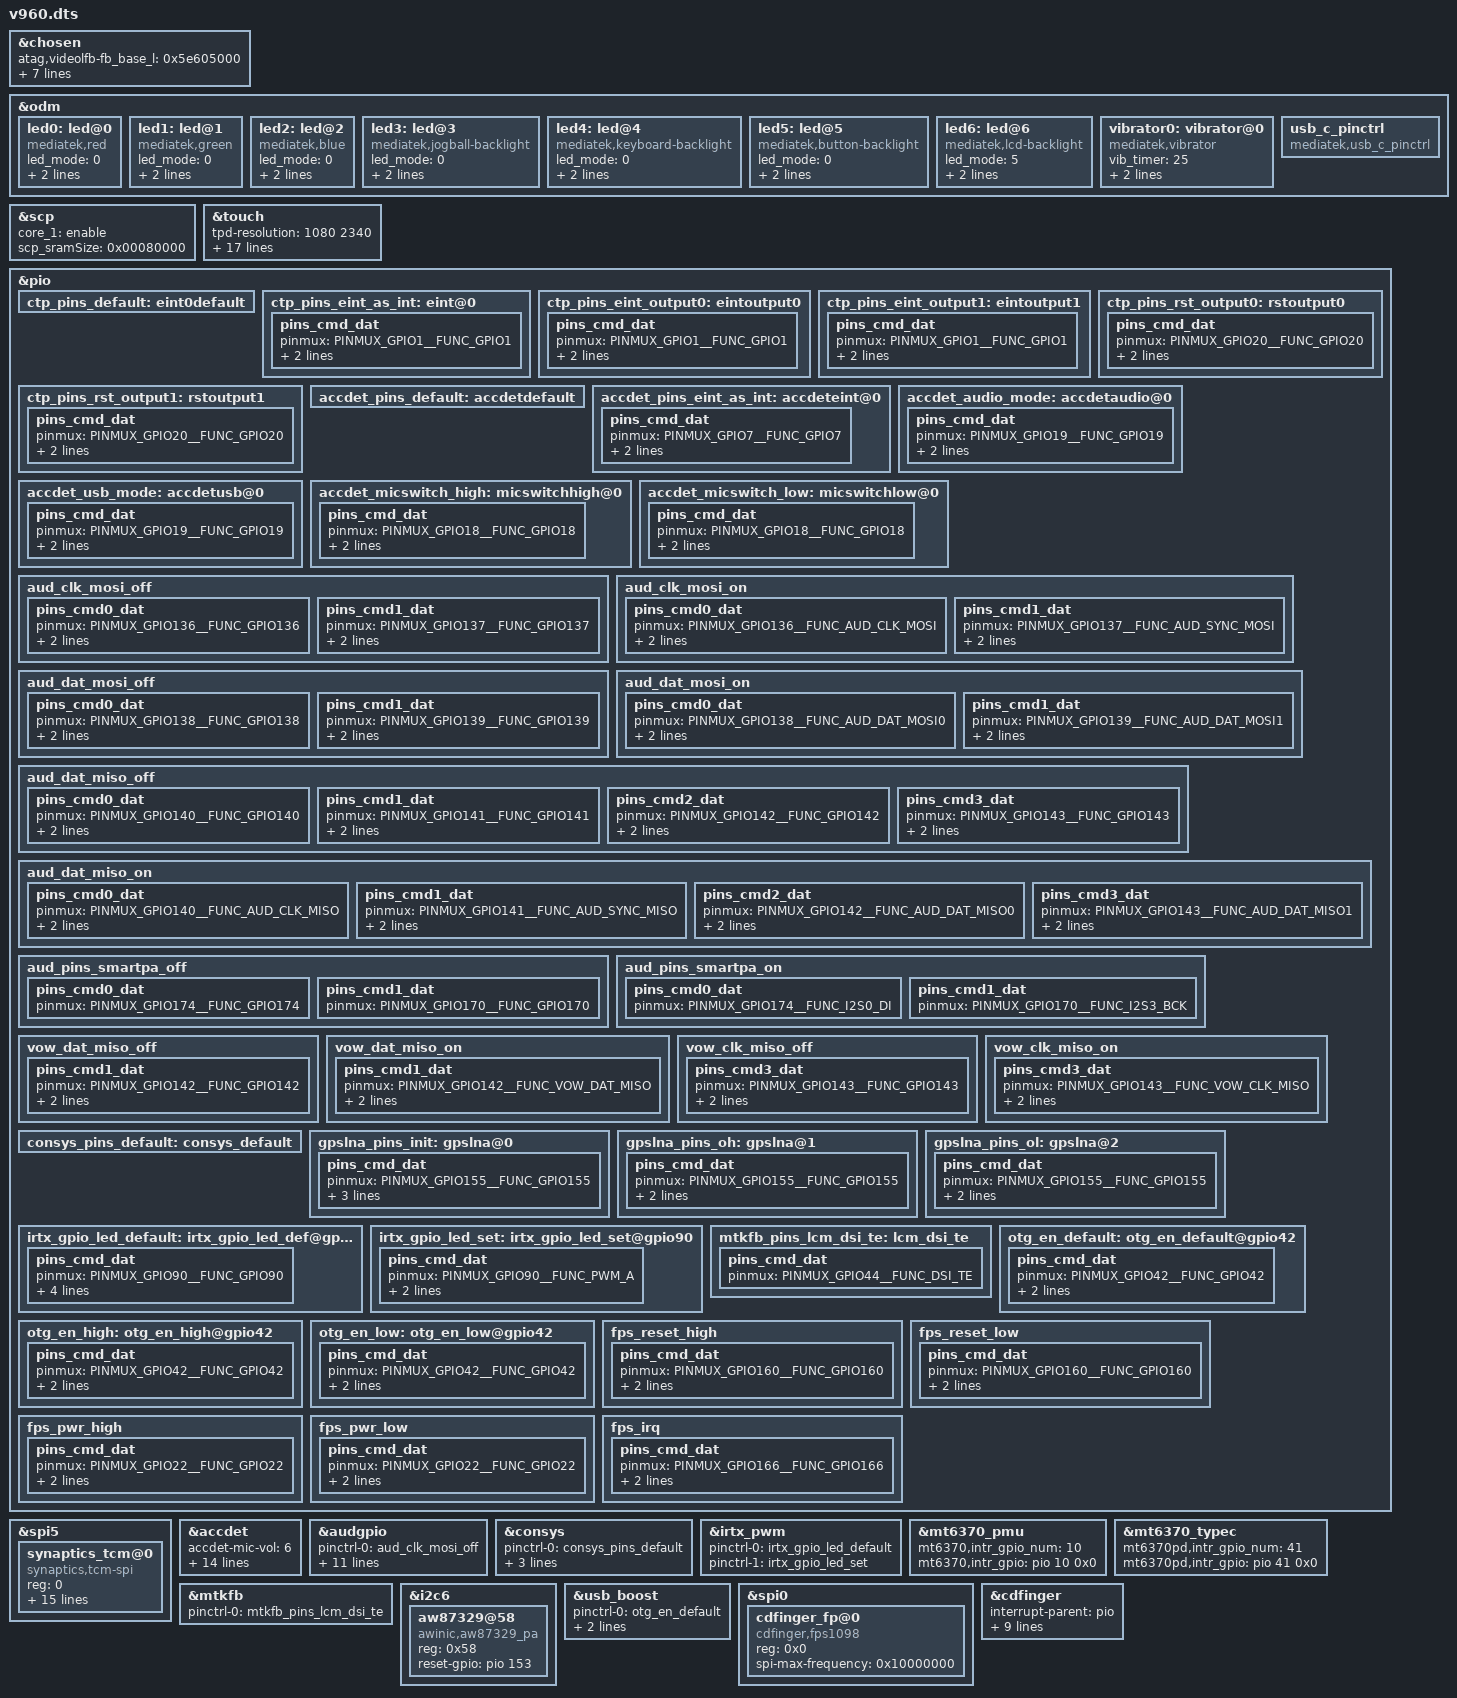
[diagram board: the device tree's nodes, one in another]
/*
 * Mediatek's mt6771 SoC device tree source
 *
 * Copyright (C) 2016 MediaTek Inc.
 *
 * This program is free software; you can redistribute it and/or modify
 * it under the terms of the GNU General Public License version 2 as
 * published by the Free Software Foundation.
 *
 * This program is distributed in the hope that it will be useful,
 * but WITHOUT ANY WARRANTY; without even the implied warranty of
 * MERCHANTABILITY or FITNESS FOR A PARTICULAR PURPOSE.
 * See http://www.gnu.org/licenses/gpl-2.0.html for more details.
 */
/dts-v1/;
/plugin/;
#include <dt-bindings/interrupt-controller/irq.h>
#include <dt-bindings/interrupt-controller/arm-gic.h>
#include <dt-bindings/pinctrl/mt6771-pinfunc.h>

/* chosen */
&chosen {
	/* fpga may has no lk, we need to specify display info here */
	/* fb buffer is reserved using this dts by memory node above */

	atag,videolfb-fb_base_l = <0x5e605000>;
	atag,videolfb-fb_base_h = <0x0>;
	atag,videolfb-islcmfound = <1>;
	atag,videolfb-islcm_inited = <0>;
	atag,videolfb-fps= <6000>;
	atag,videolfb-vramSize= <0x017bb000>;
	atag,videolfb-lcmname= "nt35595_fhd_dsi_cmd_truly_nt50358_drv";
};

&odm {
	led0:led@0 {
		compatible = "mediatek,red";
		led_mode = <0>;
		data = <1>;
		pwm_config = <0 0 0 0 0>;
	};
	led1:led@1 {
		compatible = "mediatek,green";
		led_mode = <0>;
		data = <1>;
		pwm_config = <0 0 0 0 0>;
	};
	led2:led@2 {
		compatible = "mediatek,blue";
		led_mode = <0>;
		data = <1>;
		pwm_config = <0 0 0 0 0>;
	};
	led3:led@3 {
		compatible = "mediatek,jogball-backlight";
		led_mode = <0>;
		data = <1>;
		pwm_config = <0 0 0 0 0>;
	};
	led4:led@4 {
		compatible = "mediatek,keyboard-backlight";
		led_mode = <0>;
		data = <1>;
		pwm_config = <0 0 0 0 0>;
	};
	led5:led@5 {
		compatible = "mediatek,button-backlight";
		led_mode = <0>;
		data = <1>;
		pwm_config = <0 0 0 0 0>;
	};
	led6:led@6 {
		compatible = "mediatek,lcd-backlight";
		led_mode = <5>;
		data = <1>;
		pwm_config = <0 1 0 0 0>;
	};
	vibrator0:vibrator@0 {
		compatible = "mediatek,vibrator";
		vib_timer = <25>;
		vib_limit = <9>;
		vib_vol= <9>;
	};
	usb_c_pinctrl:usb_c_pinctrl {
		compatible = "mediatek,usb_c_pinctrl";
	};
};

&scp {
	core_1 = "enable";
	scp_sramSize = <0x00080000>;     /* scp_A_sram_size */
};

/* TOUCH start */
&touch {
	tpd-resolution = <1080 2340>;
	use-tpd-button = <0>;
	tpd-key-num = <3>;
	tpd-key-local= <139 172 158 0>;
	tpd-key-dim-local = <90 883 100 40 230 883 100 40 370 883 100 40 0 0 0 0>;
	tpd-max-touch-num = <5>;
	tpd-filter-enable = <1>;
	tpd-filter-pixel-density = <146>;
	tpd-filter-custom-prameters = <0 0 0 0 0 0 0 0 0 0 0 0>;
	tpd-filter-custom-speed = <0 0 0>;
	pinctrl-names = "default", "state_eint_as_int",
		"state_eint_output0", "state_eint_output1",
		"state_rst_output0", "state_rst_output1";
	pinctrl-0 = <&ctp_pins_default>;
	pinctrl-1 = <&ctp_pins_eint_as_int>;
	pinctrl-2 = <&ctp_pins_eint_output0>;
	pinctrl-3 = <&ctp_pins_eint_output1>;
	pinctrl-4 = <&ctp_pins_rst_output0>;
	pinctrl-5 = <&ctp_pins_rst_output1>;
	status = "okay";
};
&pio {
	ctp_pins_default: eint0default {
	};
	ctp_pins_eint_as_int: eint@0 {
		pins_cmd_dat {
			pinmux = <PINMUX_GPIO1__FUNC_GPIO1>;
			slew-rate = <0>;
			bias-disable;
		};
	};
	ctp_pins_eint_output0: eintoutput0 {
		pins_cmd_dat {
			pinmux = <PINMUX_GPIO1__FUNC_GPIO1>;
			slew-rate = <1>;
			output-low;
		};
	};
	ctp_pins_eint_output1: eintoutput1 {
		pins_cmd_dat {
			pinmux = <PINMUX_GPIO1__FUNC_GPIO1>;
			slew-rate = <1>;
			output-high;
		};
	};
	ctp_pins_rst_output0: rstoutput0 {
		pins_cmd_dat {
			pinmux = <PINMUX_GPIO20__FUNC_GPIO20>;
			slew-rate = <1>;
			output-low;
		};
	};
	ctp_pins_rst_output1: rstoutput1 {
		pins_cmd_dat {
			pinmux = <PINMUX_GPIO20__FUNC_GPIO20>;
			slew-rate = <1>;
			output-high;
		};
	};
};

&spi5{
	#address-cells = <1>;
	#size-cells = <0>;
	status = "okay";
	synaptics_tcm@0 {
		compatible = "synaptics,tcm-spi";
		reg = <0>;
		spi-max-frequency = <8000000>;
		interrupt-parent = <&pio>;
		interrupts = <1 0x2008>;
		synaptics,irq-gpio = <&pio 1 0x2008>; /* IRQF_ONESHOT | IRQF_TRIGGER_LOW */
		synaptics,irq-on-state = <0>;
		synaptics,reset-gpio = <&pio 20 0x0000>;
		synaptics,reset-on-state = <0>;
		synaptics,reset-active-ms = <20>;
		synaptics,reset-delay-ms = <200>;
		synaptics,power-delay-ms = <200>;
		synaptics,spi-mode = <3>;
		synaptics,byte-delay-us = <0>;
		synaptics,block-delay-us = <0>;
		synaptics,ubl-max-freq = <100000>;
		synaptics,ubl-byte-delay-us = <0>;
		status = "okay";
	};
};
/* TOUCH end */

/* accdet start */
&accdet {
	/* accdet micbias voltage: 0x07,2.7v;0x05,2.5v;0x02,1.9v */
	accdet-mic-vol = <6>;
	headset-mode-setting = <0x500 0x500 1 0x1f0 0x800 0x800 0x20 0x44>;
	accdet-plugout-debounce = <1>;
	/*1:ACC mode, 2:low cost without in bias, 6:low cost with in bias*/
	accdet-mic-mode = <1>;
	/* eint_level_trigger: 8,LEVEL_LOW(default);4,LEVEL_HIGH;others,LEVEL_LOW */
	headset-eint-level-pol = <8>;
	/*0--MD_MAX--UP_MAX--DW_MAX*/
	headset-three-key-threshold = <0 60 200 400>;
	headset-three-key-threshold-CDD = <0 121 192 600>;
	/*0--MD_MAX--VOICE_MAX--UP_MAX--DW_MAX*/
	headset-four-key-threshold = <0 58 121 192 400>;

	pinctrl-names = "default", "state_eint_as_int", "state_audio_mode", "state_usb_mode", "state_micswitch_high", "state_micswitch_low";
	pinctrl-0 = <&accdet_pins_default>;
	pinctrl-1 = <&accdet_pins_eint_as_int>;
	pinctrl-2 = <&accdet_audio_mode>;
	pinctrl-3 = <&accdet_usb_mode>;
	pinctrl-4 = <&accdet_micswitch_high>;
	pinctrl-5 = <&accdet_micswitch_low>;
	status = "okay";
};
&pio {
	accdet_pins_default: accdetdefault {
	};
	accdet_pins_eint_as_int: accdeteint@0 {
		pins_cmd_dat {
			pinmux = <PINMUX_GPIO7__FUNC_GPIO7>;
			slew-rate = <0>;
			bias-disable;
		};
	};
	accdet_audio_mode: accdetaudio@0 {
		pins_cmd_dat {
			pinmux = <PINMUX_GPIO19__FUNC_GPIO19>;
			slew-rate = <1>;
			output-high;
		};
	};
	accdet_usb_mode: accdetusb@0 {
		pins_cmd_dat {
			pinmux = <PINMUX_GPIO19__FUNC_GPIO19>;
			slew-rate = <1>;
			output-low;
		};
	};
	accdet_micswitch_high: micswitchhigh@0 {
		pins_cmd_dat {
			pinmux = <PINMUX_GPIO18__FUNC_GPIO18>;
			slew-rate = <1>;
			output-high;
		};
	};
	accdet_micswitch_low: micswitchlow@0 {
		pins_cmd_dat {
			pinmux = <PINMUX_GPIO18__FUNC_GPIO18>;
			slew-rate = <1>;
			output-low;
		};
	};
};
/* accdet end */

/* AUDIO GPIO standardization */
&audgpio {
	pinctrl-names = "aud_clk_mosi_off",
			"aud_clk_mosi_on",
			"aud_dat_mosi_off",
			"aud_dat_mosi_on",
			"aud_dat_miso_off",
			"aud_dat_miso_on",
			"aud_smartpa_off",
			"aud_smartpa_on",
			"vow_dat_miso_off",
			"vow_dat_miso_on",
			"vow_clk_miso_off",
			"vow_clk_miso_on";
	pinctrl-0 = <&aud_clk_mosi_off>;
	pinctrl-1 = <&aud_clk_mosi_on>;
	pinctrl-2 = <&aud_dat_mosi_off>;
	pinctrl-3 = <&aud_dat_mosi_on>;
	pinctrl-4 = <&aud_dat_miso_off>;
	pinctrl-5 = <&aud_dat_miso_on>;
	pinctrl-6 = <&aud_pins_smartpa_off>;
	pinctrl-7 = <&aud_pins_smartpa_on>;
	pinctrl-8 = <&vow_dat_miso_off>;
	pinctrl-9 = <&vow_dat_miso_on>;
	pinctrl-10 = <&vow_clk_miso_off>;
	pinctrl-11 = <&vow_clk_miso_on>;
	status = "okay";
};

&pio {
	aud_clk_mosi_off: aud_clk_mosi_off {
		pins_cmd0_dat {
			pinmux = <PINMUX_GPIO136__FUNC_GPIO136>;
			input-enable;
			bias-pull-down;
		};
		pins_cmd1_dat {
			pinmux = <PINMUX_GPIO137__FUNC_GPIO137>;
			input-enable;
			bias-pull-down;
		};
	};

	aud_clk_mosi_on: aud_clk_mosi_on {
		pins_cmd0_dat {
			pinmux = <PINMUX_GPIO136__FUNC_AUD_CLK_MOSI>;
			input-schmitt-enable;
			bias-disable;
		};
		pins_cmd1_dat {
			pinmux = <PINMUX_GPIO137__FUNC_AUD_SYNC_MOSI>;
			input-schmitt-enable;
			bias-disable;
		};
	};

	aud_dat_mosi_off: aud_dat_mosi_off {
		pins_cmd0_dat {
			pinmux = <PINMUX_GPIO138__FUNC_GPIO138>;
			input-enable;
			bias-disable;
		};
		pins_cmd1_dat {
			pinmux = <PINMUX_GPIO139__FUNC_GPIO139>;
			input-enable;
			bias-pull-down;
		};
	};

	aud_dat_mosi_on: aud_dat_mosi_on {
		pins_cmd0_dat {
			pinmux = <PINMUX_GPIO138__FUNC_AUD_DAT_MOSI0>;
			input-schmitt-enable;
			bias-disable;
		};
		pins_cmd1_dat {
			pinmux = <PINMUX_GPIO139__FUNC_AUD_DAT_MOSI1>;
			input-schmitt-enable;
			bias-disable;
		};
	};

	aud_dat_miso_off: aud_dat_miso_off {
		pins_cmd0_dat {
			pinmux = <PINMUX_GPIO140__FUNC_GPIO140>;
			input-enable;
			bias-disable;
		};
		pins_cmd1_dat {
			pinmux = <PINMUX_GPIO141__FUNC_GPIO141>;
			input-enable;
			bias-disable;
		};
		pins_cmd2_dat {
			pinmux = <PINMUX_GPIO142__FUNC_GPIO142>;
			input-enable;
			bias-disable;
		};
		pins_cmd3_dat {
			pinmux = <PINMUX_GPIO143__FUNC_GPIO143>;
			input-enable;
			bias-disable;
		};
	};

	aud_dat_miso_on: aud_dat_miso_on {
		pins_cmd0_dat {
			pinmux = <PINMUX_GPIO140__FUNC_AUD_CLK_MISO>;
			input-schmitt-enable;
			bias-disable;
		};
		pins_cmd1_dat {
			pinmux = <PINMUX_GPIO141__FUNC_AUD_SYNC_MISO>;
			input-schmitt-enable;
			bias-disable;
		};
		pins_cmd2_dat {
			pinmux = <PINMUX_GPIO142__FUNC_AUD_DAT_MISO0>;
			input-schmitt-enable;
			bias-disable;
		};
		pins_cmd3_dat {
			pinmux = <PINMUX_GPIO143__FUNC_AUD_DAT_MISO1>;
			input-schmitt-enable;
			bias-disable;
		};
	};

	aud_pins_smartpa_off: aud_pins_smartpa_off {
		pins_cmd0_dat {
			pinmux = <PINMUX_GPIO174__FUNC_GPIO174>;
		};
		pins_cmd1_dat {
			pinmux = <PINMUX_GPIO170__FUNC_GPIO170>;
		};
	};

	aud_pins_smartpa_on: aud_pins_smartpa_on {
		pins_cmd0_dat {
			pinmux = <PINMUX_GPIO174__FUNC_I2S0_DI>;
		};
		pins_cmd1_dat {
			pinmux = <PINMUX_GPIO170__FUNC_I2S3_BCK>;
		};
	};

	vow_dat_miso_off: vow_dat_miso_off {
		pins_cmd1_dat {
			pinmux = <PINMUX_GPIO142__FUNC_GPIO142>;
			input-enable;
			bias-pull-down;
		};
	};

	vow_dat_miso_on: vow_dat_miso_on {
		pins_cmd1_dat {
			pinmux = <PINMUX_GPIO142__FUNC_VOW_DAT_MISO>;
			input-schmitt-enable;
			bias-disable;
		};
	};

	vow_clk_miso_off: vow_clk_miso_off {
		pins_cmd3_dat {
			pinmux = <PINMUX_GPIO143__FUNC_GPIO143>;
			input-enable;
			bias-pull-down;
		};
	};

	vow_clk_miso_on: vow_clk_miso_on {
		pins_cmd3_dat {
			pinmux = <PINMUX_GPIO143__FUNC_VOW_CLK_MISO>;
			input-schmitt-enable;
			bias-disable;
		};
	};
};
/* AUDIO end */

/* CONSYS GPIO standardization */
&pio {
	consys_pins_default: consys_default {
	};
	gpslna_pins_init: gpslna@0 {
		pins_cmd_dat {
			pinmux = <PINMUX_GPIO155__FUNC_GPIO155>;
			slew-rate = <0>;
			bias-disable;
			output-low;
		};
	};
	gpslna_pins_oh: gpslna@1 {
		pins_cmd_dat {
			pinmux = <PINMUX_GPIO155__FUNC_GPIO155>;
			slew-rate = <1>;
			output-high;
		};
	};
	gpslna_pins_ol: gpslna@2 {
		pins_cmd_dat {
			pinmux = <PINMUX_GPIO155__FUNC_GPIO155>;
			slew-rate = <1>;
			output-low;
		};
	};
};
&consys {
	pinctrl-names = "default", "gps_lna_state_init", "gps_lna_state_oh", "gps_lna_state_ol";
	pinctrl-0 = <&consys_pins_default>;
	pinctrl-1 = <&gpslna_pins_init>;
	pinctrl-2 = <&gpslna_pins_oh>;
	pinctrl-3 = <&gpslna_pins_ol>;
	status = "okay";
};
/* CONSYS end */

/* IRTX GPIO Start */
&irtx_pwm {
	pinctrl-names = "irtx_gpio_led_default", "irtx_gpio_led_set";
	pinctrl-0 = <&irtx_gpio_led_default>;
	pinctrl-1 = <&irtx_gpio_led_set>;
	status = "okay";
};
&pio {
	/* IRTX GPIO Settings -Start */
	/* default: GPIO0, output, high */
	irtx_gpio_led_default:irtx_gpio_led_def@gpio90 {
		pins_cmd_dat {
			pinmux = <PINMUX_GPIO90__FUNC_GPIO90>;
			slew-rate = <1>;
			bias-disable;
			output-low;
			input-schmitt-enable = <0>;
		};
	};

	irtx_gpio_led_set:irtx_gpio_led_set@gpio90 {
		pins_cmd_dat {
			pinmux = <PINMUX_GPIO90__FUNC_PWM_A>;
			slew-rate = <1>;
			output-high;
		};
	};
}; /* IRTX GPIO Settings -End */

&mt6370_pmu {
	mt6370,intr_gpio_num = <10>; /* direct defined GPIO num */
	mt6370,intr_gpio = <&pio 10 0x0>;
};

&mt6370_typec {
	mt6370pd,intr_gpio_num = <41>; /* direct defined GPIO num */
	mt6370pd,intr_gpio = <&pio 41 0x0>;
};

&pio {
	mtkfb_pins_lcm_dsi_te: lcm_dsi_te {
		pins_cmd_dat {
			pinmux = <PINMUX_GPIO44__FUNC_DSI_TE>;
		};
	};
};

&mtkfb {
	pinctrl-names = "mode_te_te";
	pinctrl-0 = <&mtkfb_pins_lcm_dsi_te>;
	status = "okay";
};

/* AW83729 Smart PA start */
&i2c6 {
	aw87329@58 {
		compatible = "awinic,aw87329_pa";
		reg = <0x58>;
		reset-gpio = <&pio 153 0>;
		status = "okay";
	};
};
/* AW83729 Smart PA end */

/* usb_boost_manager otg_en Start */
&usb_boost {
	pinctrl-names = "otg_en_default","drvvbus_high","drvvbus_low";
	pinctrl-0 = <&otg_en_default>;
	pinctrl-1 = <&otg_en_high>;
	pinctrl-2 = <&otg_en_low>;
	status = "okay";
};
&pio {
	otg_en_default:otg_en_default@gpio42 {
		pins_cmd_dat {
			pinmux = <PINMUX_GPIO42__FUNC_GPIO42>;
			slew-rate = <1>;
			output-low;
		};
	};

	otg_en_high:otg_en_high@gpio42 {
		pins_cmd_dat {
			pinmux = <PINMUX_GPIO42__FUNC_GPIO42>;
			slew-rate = <1>;
			output-high;
		};
	};

	otg_en_low:otg_en_low@gpio42 {
		pins_cmd_dat {
			pinmux = <PINMUX_GPIO42__FUNC_GPIO42>;
			slew-rate = <1>;
			output-low;
		};
	};
}; /* usb_boost_manager otg_en Settings -End */
/*******************cdfinger pin start****************/
&spi0{
	#address-cells = <1>;
	#size-cells = <0>;

	cdfinger_fp@0{
		compatible = "cdfinger,fps1098";
		reg = <0x0>;
		spi-max-frequency = <0x10000000>;
		status = "okay";
	};
};

&pio {
	fps_reset_high: fps_reset_high {
		pins_cmd_dat {
			pinmux = <PINMUX_GPIO160__FUNC_GPIO160>;
			slew-rate = <1>;
			output-high;
		};
	};
	fps_reset_low: fps_reset_low {
		pins_cmd_dat {
			pinmux = <PINMUX_GPIO160__FUNC_GPIO160>;
			slew-rate = <1>;
			output-low;
		};
	};
	fps_pwr_high: fps_pwr_high {
		pins_cmd_dat {
			pinmux = <PINMUX_GPIO22__FUNC_GPIO22>;
			slew-rate = <1>;
			output-high;
		};
	};
	fps_pwr_low: fps_pwr_low {
		pins_cmd_dat {
			pinmux = <PINMUX_GPIO22__FUNC_GPIO22>;
			slew-rate = <1>;
			output-low;
		};
	};
	fps_irq: fps_irq {
		pins_cmd_dat {
			pinmux = <PINMUX_GPIO166__FUNC_GPIO166>;
			slew-rate = <0>;
			bias-pull-down = <00>;
		};
	};
};

&cdfinger {
	interrupt-parent = <&pio>;
	interrupts = <166 1 1 0>;
	/*interrupts = <166 IRQ_TYPE_EDGE_RISING 1 0>;*/
	vdd_ldo_enable = <1>;
	vio_ldo_enable = <0>;
	config_spi_pin = <0>;

	pinctrl-names = "finger_rst_high", "finger_rst_low", "fp_pwr_high",	"fp_pwr_low", "eint";
	pinctrl-0 = <&fps_reset_high>;
	pinctrl-1 = <&fps_reset_low>;
	pinctrl-2 = <&fps_pwr_high>;
	pinctrl-3 = <&fps_pwr_low>;
	pinctrl-4 = <&fps_irq>;
	status = "okay";
};
/*******************cdfinger pin end****************/
#include <v960/cust.dtsi>
#include "cust_mt6771_camera.dtsi"
/*End of this file, DO NOT ADD ANYTHING HERE*/


